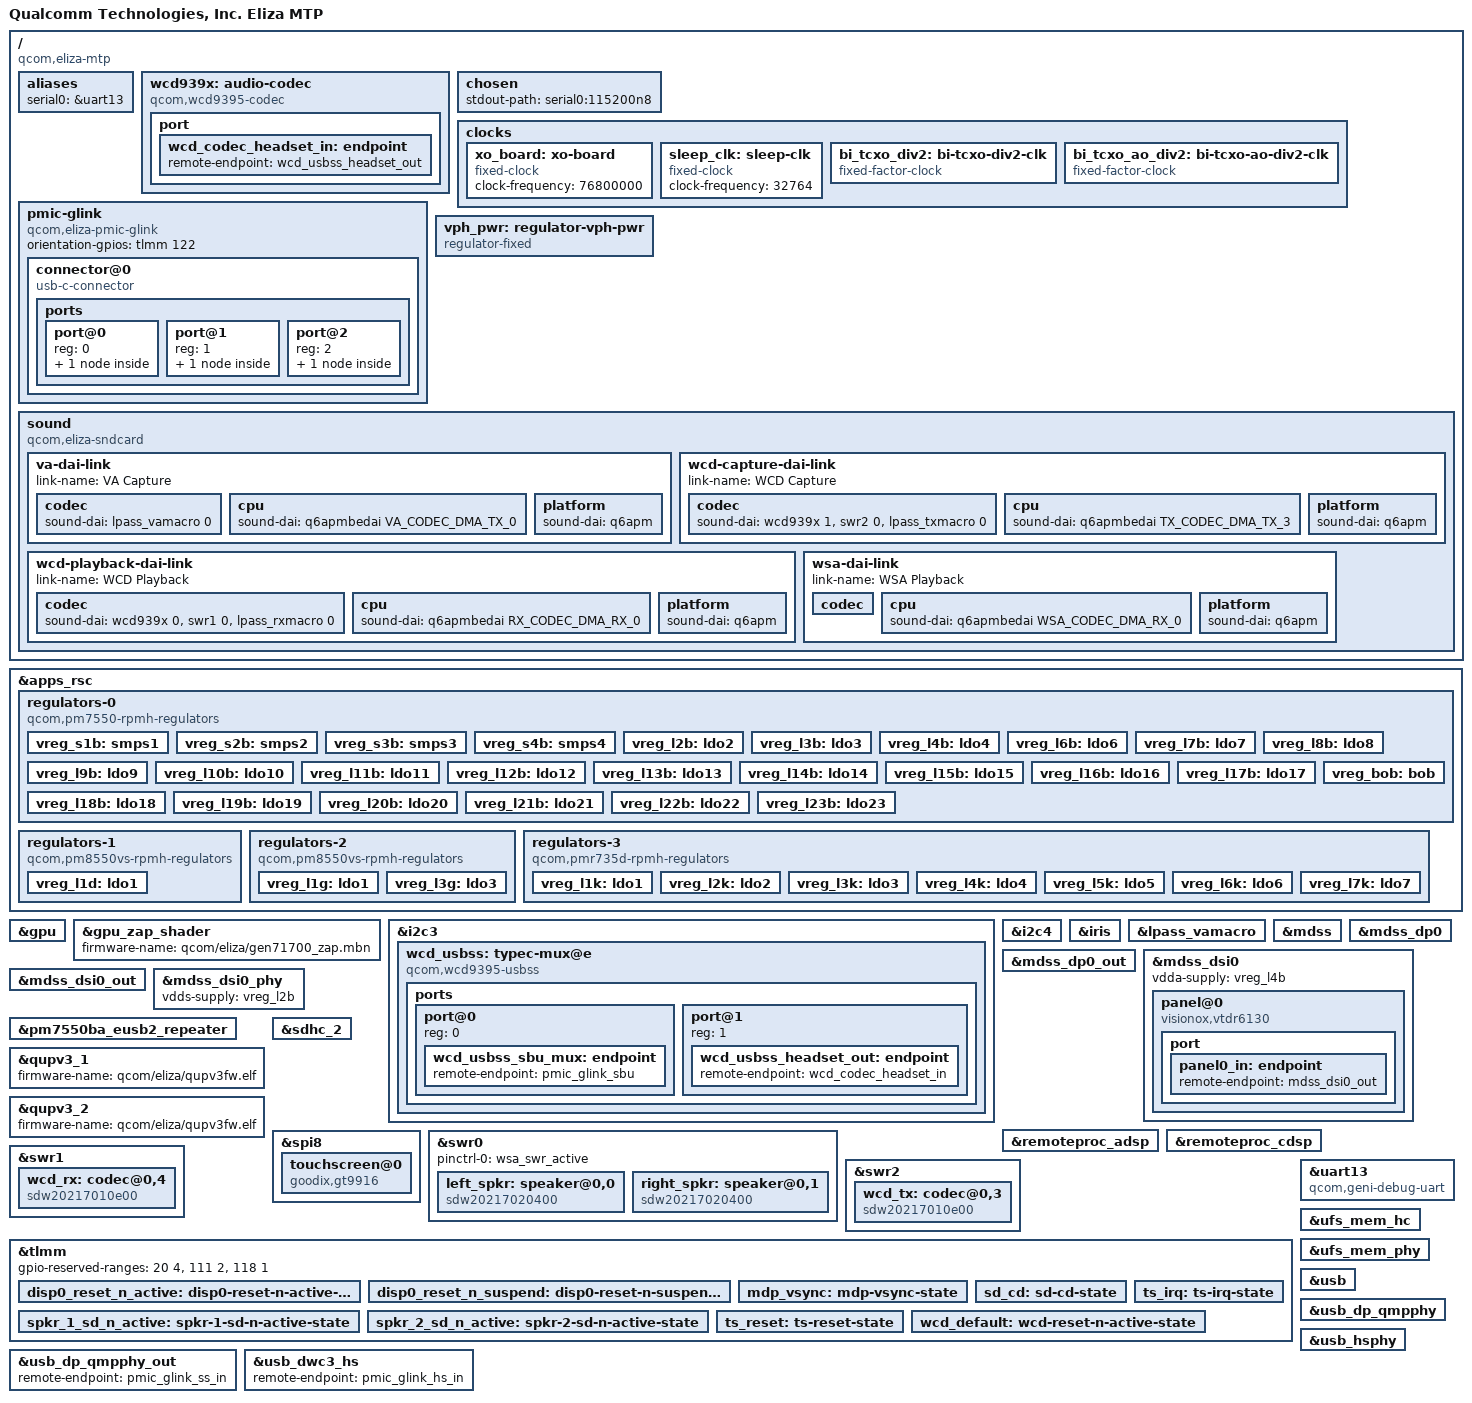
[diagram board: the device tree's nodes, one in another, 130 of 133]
// SPDX-License-Identifier: BSD-3-Clause
/*
 * Copyright (c) Qualcomm Technologies, Inc. and/or its subsidiaries.
 */

/dts-v1/;

#include <dt-bindings/gpio/gpio.h>
#include <dt-bindings/pinctrl/qcom,pmic-gpio.h>
#include <dt-bindings/regulator/qcom,rpmh-regulator.h>
#include <dt-bindings/sound/qcom,q6dsp-lpass-ports.h>
#include "eliza.dtsi"

#include "pm7550ba-eliza.dtsi"
#include "pm7550-eliza.dtsi"
#include "pm8550vs-d-eliza.dtsi"
#include "pm8550vs-g-eliza.dtsi"
#include "pmr735d-eliza.dtsi"
#include "pmk8550-eliza.dtsi"

/ {
	model = "Qualcomm Technologies, Inc. Eliza MTP";
	compatible = "qcom,eliza-mtp", "qcom,eliza";
	chassis-type = "handset";

	aliases {
		serial0 = &uart13;
	};

	wcd939x: audio-codec {
		compatible = "qcom,wcd9395-codec", "qcom,wcd9390-codec";

		pinctrl-0 = <&wcd_default>;
		pinctrl-names = "default";

		qcom,micbias1-microvolt = <1800000>;
		qcom,micbias2-microvolt = <1800000>;
		qcom,micbias3-microvolt = <1800000>;
		qcom,micbias4-microvolt = <1800000>;
		qcom,mbhc-buttons-vthreshold-microvolt = <75000 150000 237000 500000
							  500000 500000 500000 500000>;
		qcom,mbhc-headset-vthreshold-microvolt = <1700000>;
		qcom,mbhc-headphone-vthreshold-microvolt = <50000>;
		qcom,rx-device = <&wcd_rx>;
		qcom,tx-device = <&wcd_tx>;

		reset-gpios = <&tlmm 150 GPIO_ACTIVE_LOW>;

		vdd-buck-supply = <&vreg_l7b>;
		vdd-rxtx-supply = <&vreg_l7b>;
		vdd-io-supply = <&vreg_l7b>;
		vdd-mic-bias-supply = <&vreg_bob>;
		vdd-px-supply = <&vreg_l3g>;

		#sound-dai-cells = <1>;

		mode-switch;
		orientation-switch;

		port {
			wcd_codec_headset_in: endpoint {
				remote-endpoint = <&wcd_usbss_headset_out>;
			};
		};
	};

	chosen {
		stdout-path = "serial0:115200n8";
	};

	clocks {
		xo_board: xo-board {
			compatible = "fixed-clock";
			clock-frequency = <76800000>;
			#clock-cells = <0>;
		};

		sleep_clk: sleep-clk {
			compatible = "fixed-clock";
			clock-frequency = <32764>;
			#clock-cells = <0>;
		};

		bi_tcxo_div2: bi-tcxo-div2-clk {
			compatible = "fixed-factor-clock";
			#clock-cells = <0>;

			clocks = <&rpmhcc RPMH_CXO_CLK>;
			clock-mult = <1>;
			clock-div = <2>;
		};

		bi_tcxo_ao_div2: bi-tcxo-ao-div2-clk {
			compatible = "fixed-factor-clock";
			#clock-cells = <0>;

			clocks = <&rpmhcc RPMH_CXO_CLK_A>;
			clock-mult = <1>;
			clock-div = <2>;
		};
	};

	pmic-glink {
		compatible = "qcom,eliza-pmic-glink",
			     "qcom,sm8550-pmic-glink",
			     "qcom,pmic-glink";
		#address-cells = <1>;
		#size-cells = <0>;
		orientation-gpios = <&tlmm 122 GPIO_ACTIVE_HIGH>;

		connector@0 {
			compatible = "usb-c-connector";
			reg = <0>;

			power-role = "dual";
			data-role = "dual";

			ports {
				#address-cells = <1>;
				#size-cells = <0>;

				port@0 {
					reg = <0>;

					pmic_glink_hs_in: endpoint {
						remote-endpoint = <&usb_dwc3_hs>;
					};
				};

				port@1 {
					reg = <1>;

					pmic_glink_ss_in: endpoint {
						remote-endpoint = <&usb_dp_qmpphy_out>;
					};
				};

				port@2 {
					reg = <2>;

					pmic_glink_sbu: endpoint {
						remote-endpoint = <&wcd_usbss_sbu_mux>;
					};
				};
			};
		};
	};

	vph_pwr: regulator-vph-pwr {
		compatible = "regulator-fixed";

		regulator-name = "vph_pwr";
		regulator-min-microvolt = <3700000>;
		regulator-max-microvolt = <3700000>;

		regulator-always-on;
		regulator-boot-on;
	};

	sound {
		compatible = "qcom,eliza-sndcard", "qcom,sm8450-sndcard";
		model = "eliza-mtp";
		audio-routing = "SpkrLeft IN", "WSA_SPK1 OUT",
				"SpkrRight IN", "WSA_SPK2 OUT",
				"IN1_HPHL", "HPHL_OUT",
				"IN2_HPHR", "HPHR_OUT",
				"AMIC1", "MIC BIAS1",
				"AMIC2", "MIC BIAS2",
				"AMIC3", "MIC BIAS3",
				"AMIC4", "MIC BIAS1",
				"TX SWR_INPUT0", "ADC1_OUTPUT",
				"TX SWR_INPUT1", "ADC2_OUTPUT",
				"TX SWR_INPUT2", "ADC3_OUTPUT",
				"TX SWR_INPUT3", "ADC4_OUTPUT",
				"VA DMIC0", "VA MIC BIAS3",
				"VA DMIC1", "VA MIC BIAS3",
				"VA DMIC2", "VA MIC BIAS1",
				"VA DMIC3", "VA MIC BIAS1";

		va-dai-link {
			link-name = "VA Capture";

			codec {
				sound-dai = <&lpass_vamacro 0>;
			};

			cpu {
				sound-dai = <&q6apmbedai VA_CODEC_DMA_TX_0>;
			};

			platform {
				sound-dai = <&q6apm>;
			};
		};

		wcd-capture-dai-link {
			link-name = "WCD Capture";

			codec {
				sound-dai = <&wcd939x 1>, <&swr2 0>, <&lpass_txmacro 0>;
			};

			cpu {
				sound-dai = <&q6apmbedai TX_CODEC_DMA_TX_3>;
			};

			platform {
				sound-dai = <&q6apm>;
			};
		};

		wcd-playback-dai-link {
			link-name = "WCD Playback";

			codec {
				sound-dai = <&wcd939x 0>, <&swr1 0>, <&lpass_rxmacro 0>;
			};

			cpu {
				sound-dai = <&q6apmbedai RX_CODEC_DMA_RX_0>;
			};

			platform {
				sound-dai = <&q6apm>;
			};
		};

		wsa-dai-link {
			link-name = "WSA Playback";

			codec {
				sound-dai = <&left_spkr>, <&right_spkr>,
					    <&swr0 0>, <&lpass_wsamacro 0>;
			};

			cpu {
				sound-dai = <&q6apmbedai WSA_CODEC_DMA_RX_0>;
			};

			platform {
				sound-dai = <&q6apm>;
			};
		};
	};
};

&apps_rsc {
	regulators-0 {
		compatible = "qcom,pm7550-rpmh-regulators";

		vdd-l1-supply = <&vreg_s3b>;
		vdd-l2-l3-supply = <&vreg_s3b>;
		vdd-l4-l5-supply = <&vreg_s2b>;
		vdd-l6-supply = <&vreg_s2b>;
		vdd-l7-supply = <&vreg_s1b>;
		vdd-l8-supply = <&vreg_s1b>;
		vdd-l9-l10-supply = <&vreg_s1b>;
		vdd-l11-supply = <&vreg_s1b>;
		vdd-l12-l14-supply = <&vreg_bob>;
		vdd-l13-l16-supply = <&vreg_bob>;
		vdd-l15-l17-l18-l19-l20-l21-l22-l23-supply = <&vreg_bob>;
		vdd-s1-supply = <&vph_pwr>;
		vdd-s2-supply = <&vph_pwr>;
		vdd-s3-supply = <&vph_pwr>;
		vdd-s4-supply = <&vph_pwr>;
		vdd-s5-supply = <&vph_pwr>;
		vdd-s6-supply = <&vph_pwr>;

		vdd-bob-supply = <&vph_pwr>;

		qcom,pmic-id = "b";

		vreg_s1b: smps1 {
			regulator-name = "vreg_s1b";
			regulator-min-microvolt = <1850000>;
			regulator-max-microvolt = <2040000>;
			regulator-initial-mode = <RPMH_REGULATOR_MODE_HPM>;
		};

		vreg_s2b: smps2 {
			regulator-name = "vreg_s2b";
			regulator-min-microvolt = <375000>;
			regulator-max-microvolt = <2744000>;
			regulator-initial-mode = <RPMH_REGULATOR_MODE_HPM>;
		};

		vreg_s3b: smps3 {
			regulator-name = "vreg_s3b";
			regulator-min-microvolt = <375000>;
			regulator-max-microvolt = <2744000>;
			regulator-initial-mode = <RPMH_REGULATOR_MODE_HPM>;
		};

		vreg_s4b: smps4 {
			regulator-name = "vreg_s4b";
			regulator-min-microvolt = <2156000>;
			regulator-max-microvolt = <2400000>;
			regulator-initial-mode = <RPMH_REGULATOR_MODE_HPM>;
		};

		vreg_l2b: ldo2 {
			regulator-name = "vreg_l2b";
			regulator-min-microvolt = <880000>;
			regulator-max-microvolt = <950000>;
			regulator-initial-mode = <RPMH_REGULATOR_MODE_HPM>;
		};

		vreg_l3b: ldo3 {
			regulator-name = "vreg_l3b";
			regulator-min-microvolt = <880000>;
			regulator-max-microvolt = <912000>;
			regulator-initial-mode = <RPMH_REGULATOR_MODE_HPM>;
		};

		vreg_l4b: ldo4 {
			regulator-name = "vreg_l4b";
			regulator-min-microvolt = <1200000>;
			regulator-max-microvolt = <1200000>;
			regulator-initial-mode = <RPMH_REGULATOR_MODE_HPM>;
		};

		vreg_l6b: ldo6 {
			regulator-name = "vreg_l6b";
			regulator-min-microvolt = <866000>;
			regulator-max-microvolt = <958000>;
			regulator-initial-mode = <RPMH_REGULATOR_MODE_HPM>;
		};

		vreg_l7b: ldo7 {
			regulator-name = "vreg_l7b";
			regulator-min-microvolt = <1800000>;
			regulator-max-microvolt = <1800000>;
			regulator-initial-mode = <RPMH_REGULATOR_MODE_HPM>;
		};

		vreg_l8b: ldo8 {
			regulator-name = "vreg_l8b";
			regulator-min-microvolt = <1800000>;
			regulator-max-microvolt = <1800000>;
			regulator-initial-mode = <RPMH_REGULATOR_MODE_HPM>;
		};

		vreg_l9b: ldo9 {
			regulator-name = "vreg_l9b";
			regulator-min-microvolt = <1800000>;
			regulator-max-microvolt = <1800000>;
			regulator-initial-mode = <RPMH_REGULATOR_MODE_HPM>;
		};

		vreg_l10b: ldo10 {
			regulator-name = "vreg_l10b";
			regulator-min-microvolt = <1800000>;
			regulator-max-microvolt = <1800000>;
			regulator-initial-mode = <RPMH_REGULATOR_MODE_HPM>;
		};

		vreg_l11b: ldo11 {
			regulator-name = "vreg_l11b";
			regulator-min-microvolt = <1800000>;
			regulator-max-microvolt = <1800000>;
			regulator-initial-mode = <RPMH_REGULATOR_MODE_HPM>;
		};

		vreg_l12b: ldo12 {
			regulator-name = "vreg_l12b";
			/* Voltage range for UFS 3.x and above */
			regulator-min-microvolt = <2400000>;
			regulator-max-microvolt = <3300000>;
			regulator-initial-mode = <RPMH_REGULATOR_MODE_HPM>;
		};

		vreg_l13b: ldo13 {
			regulator-name = "vreg_l13b";
			regulator-min-microvolt = <2700000>;
			regulator-max-microvolt = <3300000>;
			regulator-initial-mode = <RPMH_REGULATOR_MODE_HPM>;
		};

		vreg_l14b: ldo14 {
			regulator-name = "vreg_l14b";
			regulator-min-microvolt = <3300000>;
			regulator-max-microvolt = <3304000>;
			regulator-initial-mode = <RPMH_REGULATOR_MODE_HPM>;
		};

		vreg_l15b: ldo15 {
			regulator-name = "vreg_l15b";
			regulator-min-microvolt = <3300000>;
			regulator-max-microvolt = <3304000>;
			regulator-initial-mode = <RPMH_REGULATOR_MODE_HPM>;
		};

		vreg_l16b: ldo16 {
			regulator-name = "vreg_l16b";
			regulator-min-microvolt = <3008000>;
			regulator-max-microvolt = <3008000>;
			regulator-initial-mode = <RPMH_REGULATOR_MODE_HPM>;
		};

		vreg_l17b: ldo17 {
			regulator-name = "vreg_l17b";
			regulator-min-microvolt = <3104000>;
			regulator-max-microvolt = <3104000>;
			regulator-initial-mode = <RPMH_REGULATOR_MODE_HPM>;
		};

		vreg_l18b: ldo18 {
			regulator-name = "vreg_l18b";
			regulator-min-microvolt = <2800000>;
			regulator-max-microvolt = <2800000>;
			regulator-initial-mode = <RPMH_REGULATOR_MODE_HPM>;
		};

		vreg_l19b: ldo19 {
			regulator-name = "vreg_l19b";
			regulator-min-microvolt = <3000000>;
			regulator-max-microvolt = <3000000>;
			regulator-initial-mode = <RPMH_REGULATOR_MODE_HPM>;
		};

		vreg_l20b: ldo20 {
			regulator-name = "vreg_l20b";
			regulator-min-microvolt = <1620000>;
			regulator-max-microvolt = <3544000>;
			regulator-initial-mode = <RPMH_REGULATOR_MODE_HPM>;
		};

		vreg_l21b: ldo21 {
			regulator-name = "vreg_l21b";
			regulator-min-microvolt = <1620000>;
			regulator-max-microvolt = <3544000>;
			regulator-initial-mode = <RPMH_REGULATOR_MODE_HPM>;
		};

		vreg_l22b: ldo22 {
			regulator-name = "vreg_l22b";
			regulator-min-microvolt = <3200000>;
			regulator-max-microvolt = <3200000>;
			regulator-initial-mode = <RPMH_REGULATOR_MODE_HPM>;
		};

		vreg_l23b: ldo23 {
			regulator-name = "vreg_l23b";
			regulator-min-microvolt = <1650000>;
			regulator-max-microvolt = <3544000>;
			regulator-initial-mode = <RPMH_REGULATOR_MODE_HPM>;
		};

		vreg_bob: bob {
			regulator-name = "vreg_bob";
			regulator-min-microvolt = <3008000>;
			regulator-max-microvolt = <3960000>;
			regulator-initial-mode = <RPMH_REGULATOR_MODE_HPM>;
		};
	};

	regulators-1 {
		compatible = "qcom,pm8550vs-rpmh-regulators";

		vdd-l1-supply = <&vreg_s2b>;

		qcom,pmic-id = "d";

		vreg_l1d: ldo1 {
			regulator-name = "vreg_l1d";
			regulator-min-microvolt = <1140000>;
			regulator-max-microvolt = <1260000>;
			regulator-initial-mode = <RPMH_REGULATOR_MODE_HPM>;
		};
	};

	regulators-2 {
		compatible = "qcom,pm8550vs-rpmh-regulators";

		vdd-l1-supply = <&vreg_s2b>;
		vdd-l3-supply = <&vreg_s2b>;

		qcom,pmic-id = "g";

		vreg_l1g: ldo1 {
			regulator-name = "vreg_l1g";
			regulator-min-microvolt = <1150000>;
			regulator-max-microvolt = <1260000>;
			regulator-initial-mode = <RPMH_REGULATOR_MODE_HPM>;
		};

		vreg_l3g: ldo3 {
			regulator-name = "vreg_l3g";
			regulator-min-microvolt = <1150000>;
			regulator-max-microvolt = <1260000>;
			regulator-initial-mode = <RPMH_REGULATOR_MODE_HPM>;
		};

	};

	regulators-3 {
		compatible = "qcom,pmr735d-rpmh-regulators";

		vdd-l1-l2-l5-supply = <&vreg_s3b>;
		vdd-l3-l4-supply = <&vreg_s2b>;
		vdd-l6-supply = <&vreg_s1b>;
		vdd-l7-supply = <&vreg_s3b>;

		qcom,pmic-id = "k";

		vreg_l1k: ldo1 {
			regulator-name = "vreg_l1k";
			regulator-min-microvolt = <488000>;
			regulator-max-microvolt = <912000>;
			regulator-initial-mode = <RPMH_REGULATOR_MODE_HPM>;
		};

		vreg_l2k: ldo2 {
			regulator-name = "vreg_l2k";
			regulator-min-microvolt = <920000>;
			regulator-max-microvolt = <969000>;
			regulator-initial-mode = <RPMH_REGULATOR_MODE_HPM>;
		};

		vreg_l3k: ldo3 {
			regulator-name = "vreg_l3k";
			regulator-min-microvolt = <1080000>;
			regulator-max-microvolt = <1350000>;
			regulator-initial-mode = <RPMH_REGULATOR_MODE_HPM>;
		};

		vreg_l4k: ldo4 {
			regulator-name = "vreg_l4k";
			regulator-min-microvolt = <960000>;
			regulator-max-microvolt = <1980000>;
			regulator-initial-mode = <RPMH_REGULATOR_MODE_HPM>;
		};

		vreg_l5k: ldo5 {
			regulator-name = "vreg_l5k";
			regulator-min-microvolt = <866000>;
			regulator-max-microvolt = <931000>;
			regulator-initial-mode = <RPMH_REGULATOR_MODE_HPM>;
		};

		vreg_l6k: ldo6 {
			regulator-name = "vreg_l6k";
			regulator-min-microvolt = <1100000>;
			regulator-max-microvolt = <2000000>;
			regulator-initial-mode = <RPMH_REGULATOR_MODE_HPM>;
		};

		vreg_l7k: ldo7 {
			regulator-name = "vreg_l7k";
			regulator-min-microvolt = <720000>;
			regulator-max-microvolt = <958000>;
			regulator-initial-mode = <RPMH_REGULATOR_MODE_HPM>;
		};
	};
};

&gpu {
	status = "okay";
};

&gpu_zap_shader {
	firmware-name = "qcom/eliza/gen71700_zap.mbn";
};

&i2c3 {
	status = "okay";

	wcd_usbss: typec-mux@e {
		compatible = "qcom,wcd9395-usbss", "qcom,wcd9390-usbss";
		reg = <0xe>;

		vdd-supply = <&vreg_l7b>;

		mode-switch;
		orientation-switch;

		ports {
			#address-cells = <1>;
			#size-cells = <0>;

			port@0 {
				reg = <0>;

				wcd_usbss_sbu_mux: endpoint {
					remote-endpoint = <&pmic_glink_sbu>;
				};
			};

			port@1 {
				reg = <1>;

				wcd_usbss_headset_out: endpoint {
					remote-endpoint = <&wcd_codec_headset_in>;
				};
			};
		};
	};
};

&i2c4 {
	/* The ADSP also drives this bus and needs the firmware loaded here */
	status = "okay";
};

&iris {
	status = "okay";
};

&lpass_vamacro {
	pinctrl-0 = <&dmic01_default>, <&dmic23_default>;
	pinctrl-names = "default";

	qcom,dmic-sample-rate = <4800000>;
};

&mdss {
	status = "okay";
};

&mdss_dp0 {
	status = "okay";
};

&mdss_dp0_out {
	link-frequencies = /bits/ 64 <1620000000 2700000000 5400000000 8100000000>;
};

&mdss_dsi0 {
	vdda-supply = <&vreg_l4b>;

	status = "okay";

	panel@0 {
		compatible = "visionox,vtdr6130";
		reg = <0>;

		reset-gpios = <&tlmm 12 GPIO_ACTIVE_LOW>;

		vci-supply = <&vreg_l19b>;
		vdd-supply = <&vreg_l1g>;
		vddio-supply = <&vreg_l8b>;

		pinctrl-0 = <&disp0_reset_n_active>, <&mdp_vsync>;
		pinctrl-1 = <&disp0_reset_n_suspend>, <&mdp_vsync>;
		pinctrl-names = "default", "sleep";

		port {
			panel0_in: endpoint {
				remote-endpoint = <&mdss_dsi0_out>;
			};
		};
	};
};

&mdss_dsi0_out {
	remote-endpoint = <&panel0_in>;
	data-lanes = <0 1 2 3>;
};

&mdss_dsi0_phy {
	vdds-supply = <&vreg_l2b>;

	status = "okay";
};

&pm7550ba_eusb2_repeater {
	vdd18-supply = <&vreg_l7b>;
	vdd3-supply = <&vreg_l17b>;
};

&qupv3_1 {
	firmware-name = "qcom/eliza/qupv3fw.elf";
};

&qupv3_2 {
	firmware-name = "qcom/eliza/qupv3fw.elf";
};

&remoteproc_adsp {
	firmware-name = "qcom/eliza/adsp.mbn",
			"qcom/eliza/adsp_dtb.mbn";

	status = "okay";
};

&remoteproc_cdsp {
	firmware-name = "qcom/eliza/cdsp.mbn",
			"qcom/eliza/cdsp_dtb.mbn";

	status = "okay";
};

&sdhc_2 {
	vmmc-supply = <&vreg_l13b>;
	vqmmc-supply = <&vreg_l23b>;

	cd-gpios = <&tlmm 58 GPIO_ACTIVE_LOW>;

	pinctrl-0 = <&sdc2_default>, <&sd_cd>;
	pinctrl-1 = <&sdc2_sleep>, <&sd_cd>;
	pinctrl-names = "default", "sleep";

	status = "okay";
};

&spi8 {
	status = "okay";

	touchscreen@0 {
		compatible = "goodix,gt9916";
		reg = <0>;

		interrupt-parent = <&tlmm>;
		interrupts = <13 IRQ_TYPE_LEVEL_LOW>;

		reset-gpios = <&tlmm 16 GPIO_ACTIVE_LOW>;

		avdd-supply = <&vreg_l22b>;

		spi-max-frequency = <1000000>;

		touchscreen-size-x = <1080>;
		touchscreen-size-y = <2400>;

		pinctrl-0 = <&ts_irq>, <&ts_reset>;
		pinctrl-names = "default";
	};
};

&swr0 {
	pinctrl-0 = <&wsa_swr_active>;
	pinctrl-names = "default";

	status = "okay";

	/* WSA8845, Speaker Left */
	left_spkr: speaker@0,0 {
		compatible = "sdw20217020400";
		reg = <0 0>;

		pinctrl-0 = <&spkr_1_sd_n_active>;
		pinctrl-names = "default";

		powerdown-gpios = <&tlmm 59 GPIO_ACTIVE_LOW>;

		vdd-1p8-supply = <&vreg_l7b>;
		vdd-io-supply = <&vreg_l7b>;

		#sound-dai-cells = <0>;
		sound-name-prefix = "SpkrLeft";

		/*
		 * WSA8845 Port 1 (DAC)     <=> SWR0 Port 1  (SPKR_L)
		 * WSA8845 Port 2 (COMP)    <=> SWR0 Port 2  (SPKR_L_COMP)
		 * WSA8845 Port 3 (BOOST)   <=> SWR0 Port 3  (SPKR_L_BOOST)
		 * WSA8845 Port 4 (PBR)     <=> SWR0 Port 7  (PBR)
		 * WSA8845 Port 5 (VISENSE) <=> SWR0 Port 10 (SPKR_L_VI)
		 * WSA8845 Port 6 (CPS)     <=> SWR0 Port 13 (CPS)
		 */
		qcom,port-mapping = <1 2 3 7 10 13>;
	};

	/* WSA8845, Speaker Right */
	right_spkr: speaker@0,1 {
		compatible = "sdw20217020400";
		reg = <0 1>;

		pinctrl-0 = <&spkr_2_sd_n_active>;
		pinctrl-names = "default";

		powerdown-gpios = <&tlmm 69 GPIO_ACTIVE_LOW>;

		vdd-1p8-supply = <&vreg_l7b>;
		vdd-io-supply = <&vreg_l7b>;

		#sound-dai-cells = <0>;
		sound-name-prefix = "SpkrRight";

		/*
		 * WSA8845 Port 1 (DAC)     <=> SWR0 Port 4  (SPKR_R)
		 * WSA8845 Port 2 (COMP)    <=> SWR0 Port 5  (SPKR_R_COMP)
		 * WSA8845 Port 3 (BOOST)   <=> SWR0 Port 6  (SPKR_R_BOOST)
		 * WSA8845 Port 4 (PBR)     <=> SWR0 Port 7  (PBR)
		 * WSA8845 Port 5 (VISENSE) <=> SWR0 Port 11 (SPKR_R_VI)
		 * WSA8845 Port 6 (CPS)     <=> SWR0 Port 13 (CPS)
		 */
		qcom,port-mapping = <4 5 6 7 11 13>;
	};
};

&swr1 {
	status = "okay";

	/* WCD939x RX */
	wcd_rx: codec@0,4 {
		compatible = "sdw20217010e00";
		reg = <0 4>;

		/*
		 * WCD939x RX Port 1 (HPH_L/R)      <=> SWR1 Port 1 (HPH_L/R)
		 * WCD939x RX Port 2 (CLSH)         <=> SWR1 Port 2 (CLSH)
		 * WCD939x RX Port 3 (COMP_L/R)     <=> SWR1 Port 3 (COMP_L/R)
		 * WCD939x RX Port 4 (LO)           <=> SWR1 Port 4 (LO)
		 * WCD939x RX Port 5 (DSD_L/R)      <=> SWR1 Port 5 (DSD_L/R)
		 * WCD939x RX Port 6 (HIFI_PCM_L/R) <=> SWR1 Port 9 (HIFI_PCM_L/R)
		 */
		qcom,rx-port-mapping = <1 2 3 4 5 9>;
	};
};

&swr2 {
	status = "okay";

	/* WCD939x TX */
	wcd_tx: codec@0,3 {
		compatible = "sdw20217010e00";
		reg = <0 3>;

		/*
		 * WCD939x TX Port 1 (ADC1,2)             <=> SWR2 Port 2 (TX SWR_INPUT 0,1)
		 * WCD939x TX Port 2 (ADC3,4)             <=> SWR2 Port 2 (TX SWR_INPUT 2,3)
		 * WCD939x TX Port 3 (DMIC0,1,2,3 & MBHC) <=> SWR2 Port 3 (TX SWR_INPUT 4,5,6,7)
		 * WCD939x TX Port 4 (DMIC4,5,6,7)        <=> SWR2 Port 4 (TX SWR_INPUT 8,9,10,11)
		 */
		qcom,tx-port-mapping = <2 2 3 4>;
	};
};

&tlmm {
	gpio-reserved-ranges = <20 4>,   /* NFC SPI */
			       <111 2>,  /* WCN UART1 */
			       <118 1>;  /* NFC Secure I/O */

	disp0_reset_n_active: disp0-reset-n-active-state {
		pins = "gpio12";
		function = "gpio";
		drive-strength = <8>;
		bias-disable;
	};

	disp0_reset_n_suspend: disp0-reset-n-suspend-state {
		pins = "gpio12";
		function = "gpio";
		drive-strength = <2>;
		bias-pull-down;
	};

	mdp_vsync: mdp-vsync-state {
		pins = "gpio17";
		function = "mdp_vsync";
		drive-strength = <2>;
		bias-pull-down;
	};

	sd_cd: sd-cd-state {
		pins = "gpio58";
		function = "gpio";
		bias-pull-up;
	};

	spkr_1_sd_n_active: spkr-1-sd-n-active-state {
		pins = "gpio59";
		function = "gpio";
		drive-strength = <16>;
		bias-disable;
	};

	spkr_2_sd_n_active: spkr-2-sd-n-active-state {
		pins = "gpio69";
		function = "gpio";
		drive-strength = <16>;
		bias-disable;
	};

	ts_irq: ts-irq-state {
		pins = "gpio13";
		function = "gpio";
		drive-strength = <8>;
		bias-pull-up;
		output-disable;
	};

	ts_reset: ts-reset-state {
		pins = "gpio16";
		function = "gpio";
		drive-strength = <8>;
		bias-pull-up;
	};

	wcd_default: wcd-reset-n-active-state {
		pins = "gpio150";
		function = "gpio";
		drive-strength = <16>;
		bias-disable;
		output-low;
	};
};

&uart13 {
	compatible = "qcom,geni-debug-uart";

	status = "okay";
};

&ufs_mem_hc {
	reset-gpios = <&tlmm 185 GPIO_ACTIVE_LOW>;

	vcc-supply = <&vreg_l12b>;
	vcc-max-microamp = <1300000>;
	vccq-supply = <&vreg_l1d>;
	vccq-max-microamp = <1200000>;

	status = "okay";
};

&ufs_mem_phy {
	vdda-phy-supply = <&vreg_l6b>;
	vdda-pll-supply = <&vreg_l4b>;

	status = "okay";
};

&usb {
	status = "okay";
};

&usb_dp_qmpphy {
	vdda-phy-supply = <&vreg_l7k>;
	vdda-pll-supply = <&vreg_l3g>;

	status = "okay";
};

&usb_dp_qmpphy_out {
	remote-endpoint = <&pmic_glink_ss_in>;
};

&usb_dwc3_hs {
	remote-endpoint = <&pmic_glink_hs_in>;
};

&usb_hsphy {
	vdd-supply = <&vreg_l7k>;
	vdda12-supply = <&vreg_l4b>;

	phys = <&pm7550ba_eusb2_repeater>;

	status = "okay";
};
